VERSION ""

NS_ :

BS_:

BU_: K182_PACM K43_PSCM K17_EBCM NEO K124_ASCM

BO_ 1006 ICM_100ms_PDU38: 16 iCGM
 SG_ DsttnTypOfNav : 7|4@0+ (1,0) [0|2] "NULL" Vector__XXX
 SG_ NavGudcSts : 3|1@0+ (1,0) [0|1] "NULL" Vector__XXX
 SG_ ChrgngSttnCapctOfDsttnNav : 31|8@0+ (4,0) [0|1020] "kW" Vector__XXX
 SG_ DistToDsttnNav : 43|10@0+ (0.1,0) [0|102.3] "km" Vector__XXX
 SG_ FICMOnRutWarmOffReqV : 66|1@0+ (1,0) [0|1] "NULL" Vector__XXX
 SG_ FICMChrgCtrlReq : 68|2@0+ (1,0) [0|3] "NULL" Vector__XXX
 SG_ FICMOnRutWarmOffReq : 71|2@0+ (1,0) [0|71] "NULL" Vector__XXX
 SG_ FICMChrgSttnMchngSta : 93|2@0+ (1,0) [0|3] "NULL" Vector__XXX
 SG_ FICMEleccLckCtrlReq : 95|2@0+ (1,0) [0|3] "NULL" Vector__XXX
 SG_ GudTimeToDsttnNav : 103|12@0+ (1,0) [0|4095] "Min" Vector__XXX

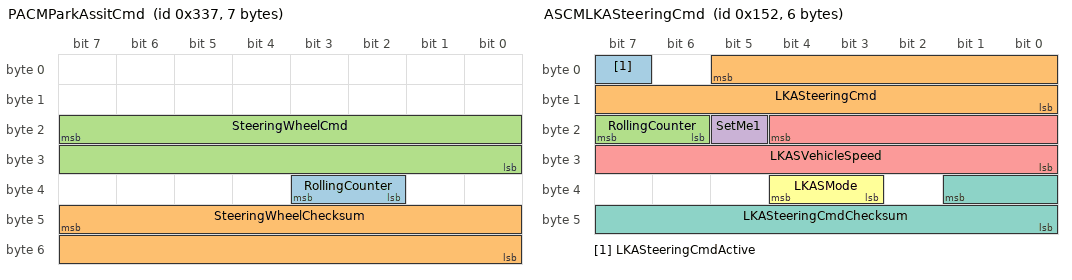
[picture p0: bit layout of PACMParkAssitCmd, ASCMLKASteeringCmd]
BO_ 823 PACMParkAssitCmd: 7 NEO
 SG_ RollingCounter : 35|2@0+ (1,0) [0|0] ""  NEO
 SG_ SteeringWheelChecksum : 47|16@0+ (1,0) [0|0] ""  NEO
 SG_ SteeringWheelCmd : 23|16@0+ (1,0) [0|0] ""  NEO

BO_ 560 EBCMRegen: 6 K17_EBCM
 SG_ Regen : 1|10@0+ (1,0) [0|0] ""  NEO

BO_ 338 ASCMLKASteeringCmd: 6 NEO
 SG_ LKASteeringCmdActive : 7|1@0+ (1,0) [0|0] ""  NEO
 SG_ LKASteeringCmd : 5|14@0- (1,0) [0|0] ""  NEO
 SG_ RollingCounter : 23|2@0+ (1,0) [0|0] ""  NEO
 SG_ SetMe1 : 21|1@0+ (1,0) [0|0] ""  NEO
 SG_ LKASVehicleSpeed : 20|13@0+ (0.22,0) [0|0] "kph" NEO
 SG_ LKASMode : 36|2@0+ (1,0) [0|0] ""  NEO
 SG_ LKASteeringCmdChecksum : 33|10@0+ (1,0) [0|0] ""  NEO

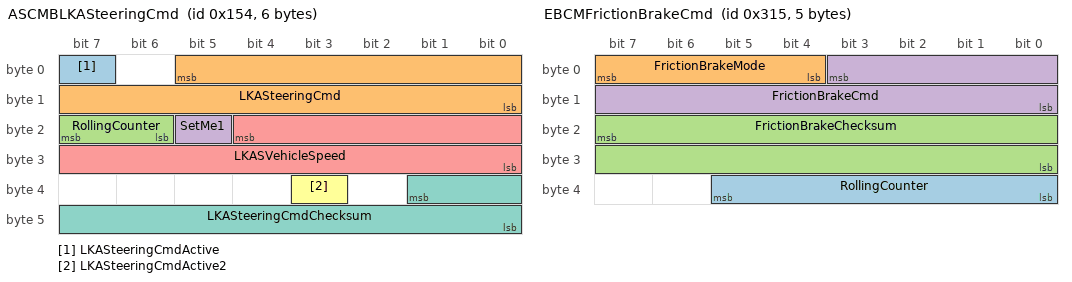
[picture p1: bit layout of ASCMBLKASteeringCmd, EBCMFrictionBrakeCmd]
BO_ 340 ASCMBLKASteeringCmd: 6 NEO
 SG_ LKASteeringCmdActive : 7|1@0+ (1,0) [0|0] ""  NEO
 SG_ LKASteeringCmd : 5|14@0- (1,0) [0|0] ""  NEO
 SG_ RollingCounter : 23|2@0+ (1,0) [0|0] ""  NEO
 SG_ SetMe1 : 21|1@0+ (1,0) [0|0] ""  NEO
 SG_ LKASVehicleSpeed : 20|13@0+ (0.22,0) [0|0] "kph" NEO
 SG_ LKASteeringCmdActive2 : 35|1@0+ (1,0) [0|0] ""  NEO
 SG_ LKASteeringCmdChecksum : 33|10@0+ (1,0) [0|0] ""  NEO

BO_ 368 EBCMFrictionBrakeStatus: 8 K17_EBCM
 SG_ FrictionBrakePressure : 23|16@0+ (1,0) [0|0] ""  NEO

BO_ 789 EBCMFrictionBrakeCmd: 5 K17_EBCM
 SG_ RollingCounter : 37|6@0+ (1,0) [0|0] ""  NEO
 SG_ FrictionBrakeMode : 7|4@0+ (1,0) [0|0] ""  NEO
 SG_ FrictionBrakeChecksum : 23|16@0+ (1,0) [0|0] ""  NEO
 SG_ FrictionBrakeCmd : 3|12@0- (1,0) [0|0] ""  NEO

BO_TX_BU_ 823 : K43_PSCM,NEO;
BO_TX_BU_ 789 : NEO,K17_EBCM;

CM_ BU_ K182_PACM "Parking Assist Control Module";
CM_ BU_ K43_PSCM "Power Steering Control Module";
CM_ BU_ K17_EBCM "Electronic Brake Control Module";
CM_ BU_ NEO "Comma NEO";
CM_ BU_ K124_ASCM "Active Safety Control Module";
BA_DEF_  "UseGMParameterIDs" INT 0 0;
BA_DEF_  "ProtocolType" STRING ;
BA_DEF_  "BusType" STRING ;
BA_DEF_DEF_  "UseGMParameterIDs" 1;
BA_DEF_DEF_  "ProtocolType" "GMLAN";
BA_DEF_DEF_  "BusType" "";
BA_ "UseGMParameterIDs" 0;
BA_ "BusType" "CAN";

VAL_ 338 LKASteeringCmdActive 1 "Active" 0 "Inactive" ;
VAL_ 338 LKASMode 2 "supercruise" 1 "lkas" 0 "Inactive" ;
